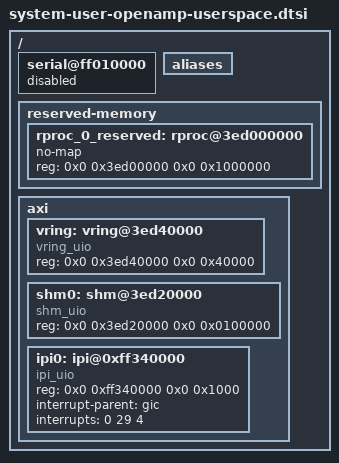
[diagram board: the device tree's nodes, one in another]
/include/ "system-conf.dtsi"
/ {

serial@ff010000 {
                status = "disabled";
                };

aliases {
                /delete-property/ serial1;
        };

reserved-memory {
		#address-cells = <2>;
		#size-cells = <2>;
		ranges;

/*
		rpu0vdev0vring0: rpu0vdev0vring0@3ed40000 {
			no-map;
			reg = <0x0 0x3ed40000 0x0 0x4000>;
		};
    rpu0vdev0vring1: rpu0vdev0vring1@3ed44000 {
			no-map;
			reg = <0x0 0x3ed44000 0x0 0x4000>;
		};
		rpu0vdev0buffer: rpu0vdev0buffer@3ed48000 {
			no-map;
			reg = <0x0 0x3ed48000 0x0 0x100000>;
		};
		rproc_0_reserved: rproc@3ed00000 {
			no-map;
			reg = <0x0 0x3ed00000 0x0 0x40000>;
		};
  };

tcm_0a: tcm_0a@ffe00000 {
		no-map;
		reg = <0x0 0xffe00000 0x0 0x10000>;
		phandle = <0x40>;
		status = "okay";
		compatible = "mmio-sram";
		power-domain = <&zynqmp_firmware 15>;
	};

tcm_0b: tcm_0b@ffe20000 {
		no-map;
		reg = <0x0 0xffe20000 0x0 0x10000>;
		phandle = <0x41>;
		status = "okay";
		compatible = "mmio-sram";
		power-domain = <&zynqmp_firmware 16>;
	};

rf5ss@ff9a0000 {
		compatible = "xlnx,zynqmp-r5-remoteproc";
		xlnx,cluster-mode = <1>;
		ranges;
		reg = <0x0 0xFF9A0000 0x0 0x10000>;
		#address-cells = <0x2>;
		#size-cells = <0x2>;
		r5f_0: r5f@0 {
			compatible = "xilinx,r5f";
			#address-cells = <2>;
			#size-cells = <2>;
			ranges;
      sram = <&tcm_0a>, <&tcm_0b>;
			memory-region = <&rproc_0_reserved>, <&rpu0vdev0buffer>, <&rpu0vdev0vring0>, <&rpu0vdev0vring1>;
			power-domain = <&zynqmp_firmware 7>;
		};
*/

  rproc_0_reserved: rproc@3ed000000 {
                                    no-map;
                                    reg = <0x0 0x3ed00000 0x0 0x1000000>;
                                    };

	};

  axi {
        /* UIO device node for vring device memory */
        vring: vring@3ed40000 {
                              compatible = "vring_uio";
                              reg = <0x0 0x3ed40000 0x0 0x40000>;
                              };
        /* Shared memory (APU to RPU) */
        shm0: shm@3ed20000 {
                    compatible = "shm_uio";
                    reg = <0x0 0x3ed20000 0x0 0x0100000>;
                    };
        /* IPI device */
        ipi0: ipi@0xff340000 {
                    compatible = "ipi_uio";
                    reg = <0x0 0xff340000 0x0 0x1000>;
                    interrupt-parent = <&gic>;
                    interrupts = <0 29 4>;
                    };
       };

};


/delete-node/ &uart1;

/*
&axi_gpio_0 {
            /delete-property/ interrupt-controller ;
            /delete-property/ interrupt-names ;
            /delete-property/ interrupt-parent ;
            /delete-property/ interrupts ;
            xlnx,interrupt-present = <0x0>;
            };

&axi_timer_0 {
             /delete-property/ interrupt-names ;
             /delete-property/ interrupt-parent ;
             /delete-property/ interrupts ;
             };
*/
